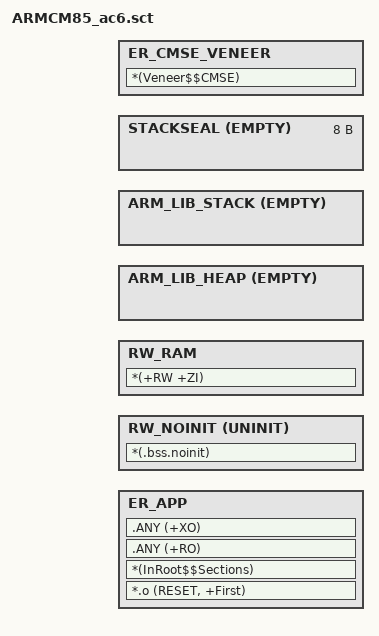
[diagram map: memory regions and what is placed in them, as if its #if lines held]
/*
 * Copyright (c) 2023 Arm Limited. All rights reserved.
 *
 * SPDX-License-Identifier: Apache-2.0
 *
 * Licensed under the Apache License, Version 2.0 (the License); you may
 * not use this file except in compliance with the License.
 * You may obtain a copy of the License at
 *
 * www.apache.org/licenses/LICENSE-2.0
 *
 * Unless required by applicable law or agreed to in writing, software
 * distributed under the License is distributed on an AS IS BASIS, WITHOUT
 * WARRANTIES OR CONDITIONS OF ANY KIND, either express or implied.
 * See the License for the specific language governing permissions and
 * limitations under the License.
 */


#if defined (__ARM_FEATURE_CMSEx) && (__ARM_FEATURE_CMSEx == 3U)
#define __STACKSEAL_SIZE   ( 8 )
#else
#define __STACKSEAL_SIZE   ( 0 )
#endif

#define __STACK_TOP  ( __RAM_BASE + __RAM_SIZE - __STACKSEAL_SIZE )  /* starts at end of RAM - 8 byte stack seal */
#define __HEAP_BASE  ( AlignExpr(+0, 8) )                            /* starts after RW_RAM or RW_NOINIT section, 8 byte aligned */


#if defined (__ARM_FEATURE_CMSEx) && (__ARM_FEATURE_CMSEx == 3U)
#define __CV_BASE          ( __ROM_BASE + __ROM_SIZE - __CMSEVENEER_SIZE )
#define __CV_SIZE          ( __CMSEVENEER_SIZE )
#else
#define __CV_BASE          ( 0xFFFFFFFF )
#define __CV_SIZE          ( 0 )
#endif

#define __LR_BASE          ( __ROM_BASE )
#define __LR_SIZE          ( __ROM_SIZE - __CV_SIZE )

#define __RW_BASE          ( __RAM_BASE )                           /* starts after noinit section */
#define __RW_SIZE          ( __RAM_SIZE - __STACK_SIZE - __HEAP_SIZE - __STACKSEAL_SIZE )


LR_APP __LR_BASE __LR_SIZE  {                                        /* load region for application */
  ER_APP __LR_BASE __LR_SIZE  {                                      /* execution region for application */
   *.o (RESET, +First)
   *(InRoot$$Sections)
   .ANY (+RO)
   .ANY (+XO)
  }

  RW_NOINIT __RW_BASE UNINIT __RW_SIZE {
    *(.bss.noinit)                                                   /* no init data */
  }

  RW_RAM AlignExpr(+0, 8) (__RW_SIZE - AlignExpr(ImageLength(RW_NOINIT), 8)) {
    *(+RW +ZI)                                                       /* RW, ZI data */
  }

#if __HEAP_SIZE > 0
  ARM_LIB_HEAP  __HEAP_BASE EMPTY  __HEAP_SIZE  {                    /* empty region for heap */
  }
#endif

  ARM_LIB_STACK __STACK_TOP EMPTY -__STACK_SIZE {                    /* empty region for stack */
  }

#if __STACKSEAL_SIZE > 0
  STACKSEAL +0 EMPTY __STACKSEAL_SIZE {                              /* empty region for stack seal immediately after stack */
  }
#endif
}

#if defined (__ARM_FEATURE_CMSEx) && (__ARM_FEATURE_CMSEx == 3U)
LR_CMSE_VENEER __CV_BASE ALIGN 32 __CV_SIZE  {                       /* load/execution region for CMSE Veneers */
  ER_CMSE_VENEER __CV_BASE __CV_SIZE  {
   *(Veneer$$CMSE)
  }
}
#endif
